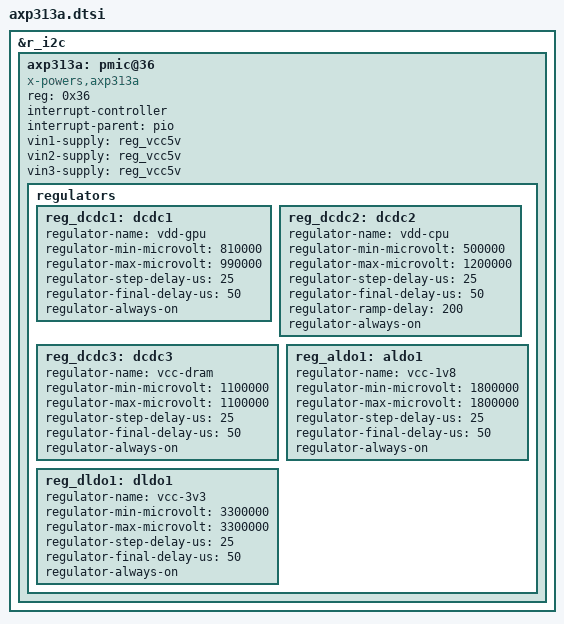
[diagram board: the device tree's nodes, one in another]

&r_i2c {
	status = "okay";

	axp313a: pmic@36 {
		compatible = "x-powers,axp313a";
		reg = <0x36>;
		#interrupt-cells = <1>;
		interrupt-controller;
		interrupt-parent = <&pio>;

		vin1-supply = <&reg_vcc5v>;
		vin2-supply = <&reg_vcc5v>;
		vin3-supply = <&reg_vcc5v>;

		regulators {
			reg_dcdc1: dcdc1 {
				regulator-name = "vdd-gpu";
				regulator-min-microvolt = <810000>;
				regulator-max-microvolt = <990000>;
				regulator-step-delay-us = <25>;
				regulator-final-delay-us = <50>;
				regulator-always-on;
			};

			reg_dcdc2: dcdc2 {
				regulator-name = "vdd-cpu";
				regulator-min-microvolt = <500000>;
				regulator-max-microvolt = <1200000>;
				regulator-step-delay-us = <25>;
				regulator-final-delay-us = <50>;
				regulator-ramp-delay = <200>;
				regulator-always-on;
			};

			reg_dcdc3: dcdc3 {
				regulator-name = "vcc-dram";
				regulator-min-microvolt = <1100000>;
				regulator-max-microvolt = <1100000>;
				regulator-step-delay-us = <25>;
				regulator-final-delay-us = <50>;
				regulator-always-on;
			};

			reg_aldo1: aldo1 {
				regulator-name = "vcc-1v8";
				regulator-min-microvolt = <1800000>;
				regulator-max-microvolt = <1800000>;
				regulator-step-delay-us = <25>;
				regulator-final-delay-us = <50>;
				regulator-always-on;
			};

			reg_dldo1: dldo1 {
				regulator-name = "vcc-3v3";
				regulator-min-microvolt = <3300000>;
				regulator-max-microvolt = <3300000>;
				regulator-step-delay-us = <25>;
				regulator-final-delay-us = <50>;
				regulator-always-on;
			};
		};
	};
};
